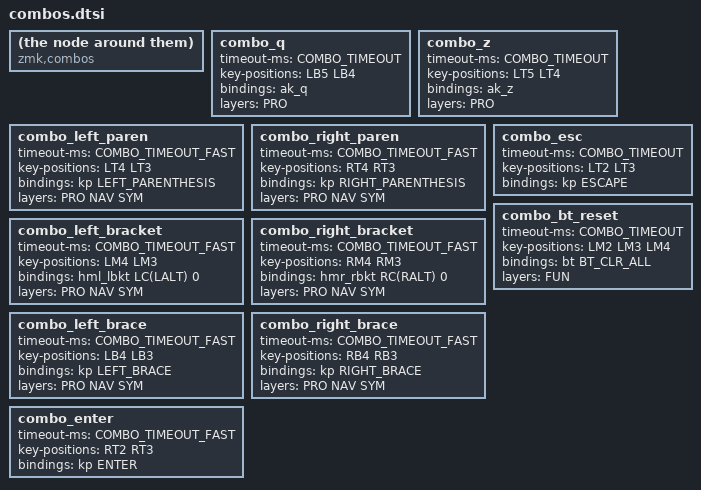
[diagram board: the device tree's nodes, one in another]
/* 
  LETTER COMBOS, PROMETHIUM LAYER
  Q, Z
*/
compatible = "zmk,combos";
combo_q {
  timeout-ms = <COMBO_TIMEOUT>;
  key-positions = <LB5 LB4>;
  bindings = <&ak_q>;
  layers = <PRO>;
};

compatible = "zmk,combos";
combo_z {
    timeout-ms = <COMBO_TIMEOUT>;
    key-positions = <LT5 LT4>;
    bindings = <&ak_z>;
    layers = <PRO>;
};




/* 
  SYMBOL AND SYMBOL MACRO COMBOS, PROMETHIUM AND NAV/NUMBER LAYERS
   
*/

/*
compatible = "zmk,combos";
combo_single_apos {
    timeout-ms = <COMBO_TIMEOUT>;
    key-positions = <LT3 LT2>;
    bindings = <&kp APOS>;
    layers = <PRO NAV SYM>;
};
*/

compatible = "zmk,combos";
combo_left_paren {
    timeout-ms = <COMBO_TIMEOUT_FAST>;
    key-positions = <LT4 LT3>;
    bindings = <&kp LEFT_PARENTHESIS>;
    layers = <PRO NAV SYM>;
};
compatible = "zmk,combos";
combo_right_paren {
    timeout-ms =<COMBO_TIMEOUT_FAST>;
    key-positions = <RT4 RT3>;
    bindings = <&kp RIGHT_PARENTHESIS>;
    layers = <PRO NAV SYM>;
};

/*
compatible = "zmk,combos";
combo_single_dbl_quotes {
    timeout-ms = <COMBO_TIMEOUT_FAST>;
    key-positions = <LM3 LM2>;
    bindings = <&kp DOUBLE_QUOTES>;
    layers = <PRO NAV SYM>;
};
*/

compatible = "zmk,combos";
combo_left_bracket {
    timeout-ms = <COMBO_TIMEOUT_FAST>;
    key-positions = <LM4 LM3>;
    bindings = <&hml_lbkt LC(LALT) 0>;
    layers = <PRO NAV SYM>;
};
compatible = "zmk,combos";
combo_right_bracket {
    timeout-ms = <COMBO_TIMEOUT_FAST>;
    key-positions = <RM4 RM3>;
    bindings = <&hmr_rbkt RC(RALT) 0>;
    layers = <PRO NAV SYM>;
};

/*
compatible = "zmk,combos";
combo_less_than {
    timeout-ms = <COMBO_TIMEOUT_FAST>;
    key-positions = <LB3 LB2>;
    bindings = <&kp LESS_THAN>;
    layers = <PRO NAV SYM>;
};
compatible = "zmk,combos";
combo_greater_than {
    timeout-ms = <COMBO_TIMEOUT_FAST>;
    key-positions = <RB3 RB2>;
    bindings = <&kp GREATER_THAN>;
    layers = <PRO NAV SYM>;
};
*/

compatible = "zmk,combos";
combo_left_brace {
    timeout-ms = <COMBO_TIMEOUT_FAST>;
    key-positions = <LB4 LB3>;
    bindings = <&kp LEFT_BRACE>;
    layers = <PRO NAV SYM>;
};

compatible = "zmk,combos";
combo_right_brace {
    timeout-ms = <COMBO_TIMEOUT_FAST>;
    key-positions = <RB4 RB3>;
    bindings = <&kp RIGHT_BRACE>;
    layers = <PRO NAV SYM>;
};


/* 
  GLOBAL COMBO
  ESCAPE, BACKSPACE, ENTER
*/

compatible = "zmk,combos";
combo_esc {
    timeout-ms = <COMBO_TIMEOUT>;
    key-positions = <LT2 LT3>;
    bindings = <&kp ESCAPE>;
};

compatible = "zmk,combos";
combo_enter {
    timeout-ms = <COMBO_TIMEOUT_FAST>;
    key-positions = <RT2 RT3>;
    bindings = <&kp ENTER>;
};

/*
  HIDDEN COMBOS
  RESET BT
*/

compatible = "zmk,combos";
combo_bt_reset {
    timeout-ms = <COMBO_TIMEOUT>;
    key-positions = <LM2 LM3 LM4>;
    bindings = <&bt BT_CLR_ALL>;
    layers = <FUN>;
};
